AUTOSAR XML (schema 4-0-3)
standard types defined: Boolean, UInt16
package /AUTOSAR_Platform/DataConstrs
  range DC_Boolean: raw 0..1
  range DC_UInt16: raw 0..65535
package /PATAC/MSM/ComponentTypes
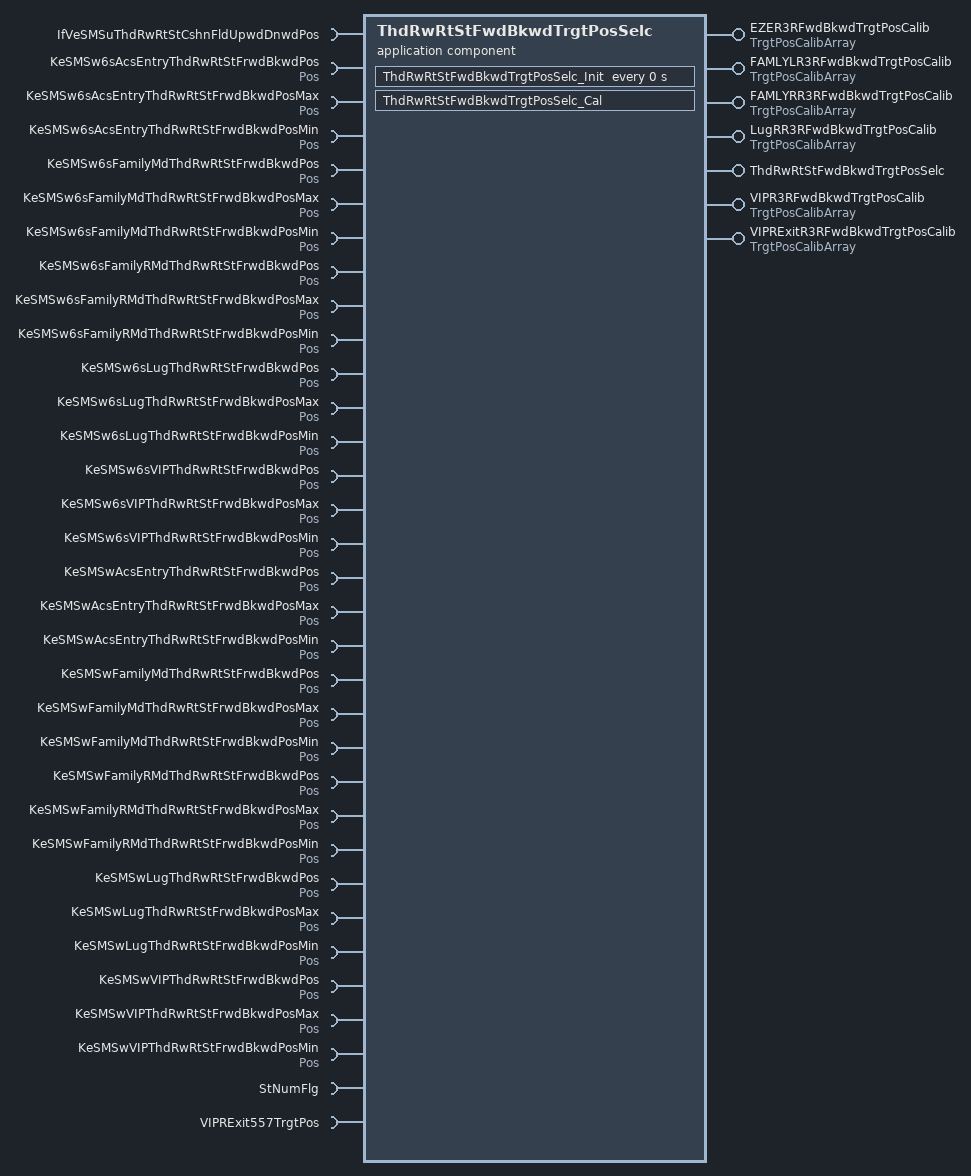
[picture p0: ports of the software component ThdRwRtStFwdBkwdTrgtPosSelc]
  application sw component type ThdRwRtStFwdBkwdTrgtPosSelc
    7 x provide port:
      EZER3RFwdBkwdTrgtPosCalib: nonqueued-sender-com-spec{data-element=TrgtPosArray, init-value=[4095, 4095, 4095]}, provided-interface=TrgtPosCalibArray
      FAMLYLR3RFwdBkwdTrgtPosCalib: nonqueued-sender-com-spec{data-element=TrgtPosArray, init-value=[4095, 4095, 4095]}, provided-interface=TrgtPosCalibArray
      FAMLYRR3RFwdBkwdTrgtPosCalib: nonqueued-sender-com-spec{data-element=TrgtPosArray, init-value=[4095, 4095, 4095]}, provided-interface=TrgtPosCalibArray
      LugRR3RFwdBkwdTrgtPosCalib: nonqueued-sender-com-spec{data-element=TrgtPosArray, init-value=[4095, 4095, 4095]}, provided-interface=TrgtPosCalibArray
      ThdRwRtStFwdBkwdTrgtPosSelc: server-com-spec{operation=Cal, queue-length=1}, provided-interface=ThdRwRtStFwdBkwdTrgtPosSelc
      VIPR3RFwdBkwdTrgtPosCalib: nonqueued-sender-com-spec{data-element=TrgtPosArray, init-value=[4095, 4095, 4095]}, provided-interface=TrgtPosCalibArray
      VIPRExitR3RFwdBkwdTrgtPosCalib: nonqueued-sender-com-spec{data-element=TrgtPosArray, init-value=[4095, 4095, 4095]}, provided-interface=TrgtPosCalibArray
    33 x require port:
      IfVeSMSuThdRwRtStCshnFldUpwdDnwdPos: nonqueued-receiver-com-spec{data-element=Val, filter=data-filter-type=ALWAYS, init-value=0}, required-interface=IfVeSMSuThdRwRtStCshnFldUpwdDnwdPos
      KeSMSw6sAcsEntryThdRwRtStFrwdBkwdPos: parameter-require-com-spec{init-value=2760, parameter=Val}, required-interface=Pos
      KeSMSw6sAcsEntryThdRwRtStFrwdBkwdPosMax: parameter-require-com-spec{init-value=4000, parameter=Val}, required-interface=Pos
      KeSMSw6sAcsEntryThdRwRtStFrwdBkwdPosMin: parameter-require-com-spec{init-value=2760, parameter=Val}, required-interface=Pos
      KeSMSw6sFamilyMdThdRwRtStFrwdBkwdPos: parameter-require-com-spec{init-value=0, parameter=Val}, required-interface=Pos
      KeSMSw6sFamilyMdThdRwRtStFrwdBkwdPosMax: parameter-require-com-spec{init-value=0, parameter=Val}, required-interface=Pos
      KeSMSw6sFamilyMdThdRwRtStFrwdBkwdPosMin: parameter-require-com-spec{init-value=0, parameter=Val}, required-interface=Pos
      KeSMSw6sFamilyRMdThdRwRtStFrwdBkwdPos: parameter-require-com-spec{init-value=0, parameter=Val}, required-interface=Pos
      KeSMSw6sFamilyRMdThdRwRtStFrwdBkwdPosMax: parameter-require-com-spec{init-value=0, parameter=Val}, required-interface=Pos
      KeSMSw6sFamilyRMdThdRwRtStFrwdBkwdPosMin: parameter-require-com-spec{init-value=0, parameter=Val}, required-interface=Pos
      KeSMSw6sLugThdRwRtStFrwdBkwdPos: parameter-require-com-spec{init-value=0, parameter=Val}, required-interface=Pos
      KeSMSw6sLugThdRwRtStFrwdBkwdPosMax: parameter-require-com-spec{init-value=0, parameter=Val}, required-interface=Pos
      KeSMSw6sLugThdRwRtStFrwdBkwdPosMin: parameter-require-com-spec{init-value=0, parameter=Val}, required-interface=Pos
      KeSMSw6sVIPThdRwRtStFrwdBkwdPos: parameter-require-com-spec{init-value=4000, parameter=Val}, required-interface=Pos
      KeSMSw6sVIPThdRwRtStFrwdBkwdPosMax: parameter-require-com-spec{init-value=4000, parameter=Val}, required-interface=Pos
      KeSMSw6sVIPThdRwRtStFrwdBkwdPosMin: parameter-require-com-spec{init-value=4000, parameter=Val}, required-interface=Pos
      KeSMSwAcsEntryThdRwRtStFrwdBkwdPos: parameter-require-com-spec{init-value=2760, parameter=Val}, required-interface=Pos
      KeSMSwAcsEntryThdRwRtStFrwdBkwdPosMax: parameter-require-com-spec{init-value=4000, parameter=Val}, required-interface=Pos
      KeSMSwAcsEntryThdRwRtStFrwdBkwdPosMin: parameter-require-com-spec{init-value=2760, parameter=Val}, required-interface=Pos
      KeSMSwFamilyMdThdRwRtStFrwdBkwdPos: parameter-require-com-spec{init-value=0, parameter=Val}, required-interface=Pos
      KeSMSwFamilyMdThdRwRtStFrwdBkwdPosMax: parameter-require-com-spec{init-value=0, parameter=Val}, required-interface=Pos
      KeSMSwFamilyMdThdRwRtStFrwdBkwdPosMin: parameter-require-com-spec{init-value=0, parameter=Val}, required-interface=Pos
      KeSMSwFamilyRMdThdRwRtStFrwdBkwdPos: parameter-require-com-spec{init-value=0, parameter=Val}, required-interface=Pos
      KeSMSwFamilyRMdThdRwRtStFrwdBkwdPosMax: parameter-require-com-spec{init-value=0, parameter=Val}, required-interface=Pos
      KeSMSwFamilyRMdThdRwRtStFrwdBkwdPosMin: parameter-require-com-spec{init-value=0, parameter=Val}, required-interface=Pos
      KeSMSwLugThdRwRtStFrwdBkwdPos: parameter-require-com-spec{init-value=0, parameter=Val}, required-interface=Pos
      KeSMSwLugThdRwRtStFrwdBkwdPosMax: parameter-require-com-spec{init-value=0, parameter=Val}, required-interface=Pos
      KeSMSwLugThdRwRtStFrwdBkwdPosMin: parameter-require-com-spec{init-value=0, parameter=Val}, required-interface=Pos
      KeSMSwVIPThdRwRtStFrwdBkwdPos: parameter-require-com-spec{init-value=4000, parameter=Val}, required-interface=Pos
      KeSMSwVIPThdRwRtStFrwdBkwdPosMax: parameter-require-com-spec{init-value=4000, parameter=Val}, required-interface=Pos
      KeSMSwVIPThdRwRtStFrwdBkwdPosMin: parameter-require-com-spec{init-value=4000, parameter=Val}, required-interface=Pos
      StNumFlg: required-interface=StNumFlg
        required-com-specs:
          data-element=Is4s, filter=data-filter-type=ALWAYS, init-value=0
          data-element=Is6s, filter=data-filter-type=ALWAYS, init-value=0
          data-element=Is6s7s, filter=data-filter-type=ALWAYS, init-value=0
          data-element=Is7s, filter=data-filter-type=ALWAYS, init-value=0
      VIPRExit557TrgtPos: required-com-specs=[Get, Set], required-interface=VIPRExit557TrgtPos
    behavior ThdRwRtStFwdBkwdTrgtPosSelc_InternalBehavior
      operation invoked event OIT_ThdRwRtStFwdBkwdTrgtPosSelc_Cal_ThdRwRtStFwdBkwdTrgtPosSelc_Cal: start-on-event=ThdRwRtStFwdBkwdTrgtPosSelc_Cal, operation=ThdRwRtStFwdBkwdTrgtPosSelc.Cal
      timing event ThdRwRtStFwdBkwdTrgtPosSelc_InitEvent: start-on-event=ThdRwRtStFwdBkwdTrgtPosSelc_Init, period=0
      runnable ThdRwRtStFwdBkwdTrgtPosSelc_Cal
        data-receive-point-by-arguments:
          5 x access:
            REC_IfVeSMSuThdRwRtStCshnFldUpwdDnwdPos_Val: accessed-variable=IfVeSMSuThdRwRtStCshnFldUpwdDnwdPos.Val
            REC_StNumFlg_Is4s: accessed-variable=StNumFlg.Is4s
            REC_StNumFlg_Is6s: accessed-variable=StNumFlg.Is6s
            REC_StNumFlg_Is6s7s: accessed-variable=StNumFlg.Is6s7s
            REC_StNumFlg_Is7s: accessed-variable=StNumFlg.Is7s
        data-send-points:
          6 x access:
            SEND_EZER3RFwdBkwdTrgtPosCalib_TrgtPosArray: accessed-variable=EZER3RFwdBkwdTrgtPosCalib.TrgtPosArray
            SEND_FAMLYLR3RFwdBkwdTrgtPosCalib_TrgtPosArray: accessed-variable=FAMLYLR3RFwdBkwdTrgtPosCalib.TrgtPosArray
            SEND_FAMLYRR3RFwdBkwdTrgtPosCalib_TrgtPosArray: accessed-variable=FAMLYRR3RFwdBkwdTrgtPosCalib.TrgtPosArray
            SEND_LugRR3RFwdBkwdTrgtPosCalib_TrgtPosArray: accessed-variable=LugRR3RFwdBkwdTrgtPosCalib.TrgtPosArray
            SEND_VIPR3RFwdBkwdTrgtPosCalib_TrgtPosArray: accessed-variable=VIPR3RFwdBkwdTrgtPosCalib.TrgtPosArray
            SEND_VIPRExitR3RFwdBkwdTrgtPosCalib_TrgtPosArray: accessed-variable=VIPRExitR3RFwdBkwdTrgtPosCalib.TrgtPosArray
        30 x parameter access:
          PA_KeSMSw6sAcsEntryThdRwRtStFrwdBkwdPos_Val: accessed-parameter=KeSMSw6sAcsEntryThdRwRtStFrwdBkwdPos.Val
          PA_KeSMSw6sAcsEntryThdRwRtStFrwdBkwdPosMax_Val: accessed-parameter=KeSMSw6sAcsEntryThdRwRtStFrwdBkwdPosMax.Val
          PA_KeSMSw6sAcsEntryThdRwRtStFrwdBkwdPosMin_Val: accessed-parameter=KeSMSw6sAcsEntryThdRwRtStFrwdBkwdPosMin.Val
          PA_KeSMSw6sFamilyMdThdRwRtStFrwdBkwdPos_Val: accessed-parameter=KeSMSw6sFamilyMdThdRwRtStFrwdBkwdPos.Val
          PA_KeSMSw6sFamilyMdThdRwRtStFrwdBkwdPosMax_Val: accessed-parameter=KeSMSw6sFamilyMdThdRwRtStFrwdBkwdPosMax.Val
          PA_KeSMSw6sFamilyMdThdRwRtStFrwdBkwdPosMin_Val: accessed-parameter=KeSMSw6sFamilyMdThdRwRtStFrwdBkwdPosMin.Val
          PA_KeSMSw6sFamilyRMdThdRwRtStFrwdBkwdPos_Val: accessed-parameter=KeSMSw6sFamilyRMdThdRwRtStFrwdBkwdPos.Val
          PA_KeSMSw6sFamilyRMdThdRwRtStFrwdBkwdPosMax_Val: accessed-parameter=KeSMSw6sFamilyRMdThdRwRtStFrwdBkwdPosMax.Val
          PA_KeSMSw6sFamilyRMdThdRwRtStFrwdBkwdPosMin_Val: accessed-parameter=KeSMSw6sFamilyRMdThdRwRtStFrwdBkwdPosMin.Val
          PA_KeSMSw6sLugThdRwRtStFrwdBkwdPos_Val: accessed-parameter=KeSMSw6sLugThdRwRtStFrwdBkwdPos.Val
          PA_KeSMSw6sLugThdRwRtStFrwdBkwdPosMax_Val: accessed-parameter=KeSMSw6sLugThdRwRtStFrwdBkwdPosMax.Val
          PA_KeSMSw6sLugThdRwRtStFrwdBkwdPosMin_Val: accessed-parameter=KeSMSw6sLugThdRwRtStFrwdBkwdPosMin.Val
          PA_KeSMSw6sVIPThdRwRtStFrwdBkwdPos_Val: accessed-parameter=KeSMSw6sVIPThdRwRtStFrwdBkwdPos.Val
          PA_KeSMSw6sVIPThdRwRtStFrwdBkwdPosMax_Val: accessed-parameter=KeSMSw6sVIPThdRwRtStFrwdBkwdPosMax.Val
          PA_KeSMSw6sVIPThdRwRtStFrwdBkwdPosMin_Val: accessed-parameter=KeSMSw6sVIPThdRwRtStFrwdBkwdPosMin.Val
          PA_KeSMSwAcsEntryThdRwRtStFrwdBkwdPos_Val: accessed-parameter=KeSMSwAcsEntryThdRwRtStFrwdBkwdPos.Val
          PA_KeSMSwAcsEntryThdRwRtStFrwdBkwdPosMax_Val: accessed-parameter=KeSMSwAcsEntryThdRwRtStFrwdBkwdPosMax.Val
          PA_KeSMSwAcsEntryThdRwRtStFrwdBkwdPosMin_Val: accessed-parameter=KeSMSwAcsEntryThdRwRtStFrwdBkwdPosMin.Val
          PA_KeSMSwFamilyMdThdRwRtStFrwdBkwdPos_Val: accessed-parameter=KeSMSwFamilyMdThdRwRtStFrwdBkwdPos.Val
          PA_KeSMSwFamilyMdThdRwRtStFrwdBkwdPosMax_Val: accessed-parameter=KeSMSwFamilyMdThdRwRtStFrwdBkwdPosMax.Val
          PA_KeSMSwFamilyMdThdRwRtStFrwdBkwdPosMin_Val: accessed-parameter=KeSMSwFamilyMdThdRwRtStFrwdBkwdPosMin.Val
          PA_KeSMSwFamilyRMdThdRwRtStFrwdBkwdPos_Val: accessed-parameter=KeSMSwFamilyRMdThdRwRtStFrwdBkwdPos.Val
          PA_KeSMSwFamilyRMdThdRwRtStFrwdBkwdPosMax_Val: accessed-parameter=KeSMSwFamilyRMdThdRwRtStFrwdBkwdPosMax.Val
          PA_KeSMSwFamilyRMdThdRwRtStFrwdBkwdPosMin_Val: accessed-parameter=KeSMSwFamilyRMdThdRwRtStFrwdBkwdPosMin.Val
          PA_KeSMSwLugThdRwRtStFrwdBkwdPos_Val: accessed-parameter=KeSMSwLugThdRwRtStFrwdBkwdPos.Val
          PA_KeSMSwLugThdRwRtStFrwdBkwdPosMax_Val: accessed-parameter=KeSMSwLugThdRwRtStFrwdBkwdPosMax.Val
          PA_KeSMSwLugThdRwRtStFrwdBkwdPosMin_Val: accessed-parameter=KeSMSwLugThdRwRtStFrwdBkwdPosMin.Val
          PA_KeSMSwVIPThdRwRtStFrwdBkwdPos_Val: accessed-parameter=KeSMSwVIPThdRwRtStFrwdBkwdPos.Val
          PA_KeSMSwVIPThdRwRtStFrwdBkwdPosMax_Val: accessed-parameter=KeSMSwVIPThdRwRtStFrwdBkwdPosMax.Val
          PA_KeSMSwVIPThdRwRtStFrwdBkwdPosMin_Val: accessed-parameter=KeSMSwVIPThdRwRtStFrwdBkwdPosMin.Val
        sync call SC_VIPRExit557TrgtPos_Get: operation=VIPRExit557TrgtPos.Get, timeout=0
      runnable ThdRwRtStFwdBkwdTrgtPosSelc_Init
        30 x parameter access:
          PA_KeSMSw6sAcsEntryThdRwRtStFrwdBkwdPos_Val: accessed-parameter=KeSMSw6sAcsEntryThdRwRtStFrwdBkwdPos.Val
          PA_KeSMSw6sAcsEntryThdRwRtStFrwdBkwdPosMax_Val: accessed-parameter=KeSMSw6sAcsEntryThdRwRtStFrwdBkwdPosMax.Val
          PA_KeSMSw6sAcsEntryThdRwRtStFrwdBkwdPosMin_Val: accessed-parameter=KeSMSw6sAcsEntryThdRwRtStFrwdBkwdPosMin.Val
          PA_KeSMSw6sFamilyMdThdRwRtStFrwdBkwdPos_Val: accessed-parameter=KeSMSw6sFamilyMdThdRwRtStFrwdBkwdPos.Val
          PA_KeSMSw6sFamilyMdThdRwRtStFrwdBkwdPosMax_Val: accessed-parameter=KeSMSw6sFamilyMdThdRwRtStFrwdBkwdPosMax.Val
          PA_KeSMSw6sFamilyMdThdRwRtStFrwdBkwdPosMin_Val: accessed-parameter=KeSMSw6sFamilyMdThdRwRtStFrwdBkwdPosMin.Val
          PA_KeSMSw6sFamilyRMdThdRwRtStFrwdBkwdPos_Val: accessed-parameter=KeSMSw6sFamilyRMdThdRwRtStFrwdBkwdPos.Val
          PA_KeSMSw6sFamilyRMdThdRwRtStFrwdBkwdPosMax_Val: accessed-parameter=KeSMSw6sFamilyRMdThdRwRtStFrwdBkwdPosMax.Val
          PA_KeSMSw6sFamilyRMdThdRwRtStFrwdBkwdPosMin_Val: accessed-parameter=KeSMSw6sFamilyRMdThdRwRtStFrwdBkwdPosMin.Val
          PA_KeSMSw6sLugThdRwRtStFrwdBkwdPos_Val: accessed-parameter=KeSMSw6sLugThdRwRtStFrwdBkwdPos.Val
          PA_KeSMSw6sLugThdRwRtStFrwdBkwdPosMax_Val: accessed-parameter=KeSMSw6sLugThdRwRtStFrwdBkwdPosMax.Val
          PA_KeSMSw6sLugThdRwRtStFrwdBkwdPosMin_Val: accessed-parameter=KeSMSw6sLugThdRwRtStFrwdBkwdPosMin.Val
          PA_KeSMSw6sVIPThdRwRtStFrwdBkwdPos_Val: accessed-parameter=KeSMSw6sVIPThdRwRtStFrwdBkwdPos.Val
          PA_KeSMSw6sVIPThdRwRtStFrwdBkwdPosMax_Val: accessed-parameter=KeSMSw6sVIPThdRwRtStFrwdBkwdPosMax.Val
          PA_KeSMSw6sVIPThdRwRtStFrwdBkwdPosMin_Val: accessed-parameter=KeSMSw6sVIPThdRwRtStFrwdBkwdPosMin.Val
          PA_KeSMSwAcsEntryThdRwRtStFrwdBkwdPos_Val: accessed-parameter=KeSMSwAcsEntryThdRwRtStFrwdBkwdPos.Val
          PA_KeSMSwAcsEntryThdRwRtStFrwdBkwdPosMax_Val: accessed-parameter=KeSMSwAcsEntryThdRwRtStFrwdBkwdPosMax.Val
          PA_KeSMSwAcsEntryThdRwRtStFrwdBkwdPosMin_Val: accessed-parameter=KeSMSwAcsEntryThdRwRtStFrwdBkwdPosMin.Val
          PA_KeSMSwFamilyMdThdRwRtStFrwdBkwdPos_Val: accessed-parameter=KeSMSwFamilyMdThdRwRtStFrwdBkwdPos.Val
          PA_KeSMSwFamilyMdThdRwRtStFrwdBkwdPosMax_Val: accessed-parameter=KeSMSwFamilyMdThdRwRtStFrwdBkwdPosMax.Val
          PA_KeSMSwFamilyMdThdRwRtStFrwdBkwdPosMin_Val: accessed-parameter=KeSMSwFamilyMdThdRwRtStFrwdBkwdPosMin.Val
          PA_KeSMSwFamilyRMdThdRwRtStFrwdBkwdPos_Val: accessed-parameter=KeSMSwFamilyRMdThdRwRtStFrwdBkwdPos.Val
          PA_KeSMSwFamilyRMdThdRwRtStFrwdBkwdPosMax_Val: accessed-parameter=KeSMSwFamilyRMdThdRwRtStFrwdBkwdPosMax.Val
          PA_KeSMSwFamilyRMdThdRwRtStFrwdBkwdPosMin_Val: accessed-parameter=KeSMSwFamilyRMdThdRwRtStFrwdBkwdPosMin.Val
          PA_KeSMSwLugThdRwRtStFrwdBkwdPos_Val: accessed-parameter=KeSMSwLugThdRwRtStFrwdBkwdPos.Val
          PA_KeSMSwLugThdRwRtStFrwdBkwdPosMax_Val: accessed-parameter=KeSMSwLugThdRwRtStFrwdBkwdPosMax.Val
          PA_KeSMSwLugThdRwRtStFrwdBkwdPosMin_Val: accessed-parameter=KeSMSwLugThdRwRtStFrwdBkwdPosMin.Val
          PA_KeSMSwVIPThdRwRtStFrwdBkwdPos_Val: accessed-parameter=KeSMSwVIPThdRwRtStFrwdBkwdPos.Val
          PA_KeSMSwVIPThdRwRtStFrwdBkwdPosMax_Val: accessed-parameter=KeSMSwVIPThdRwRtStFrwdBkwdPosMax.Val
          PA_KeSMSwVIPThdRwRtStFrwdBkwdPosMin_Val: accessed-parameter=KeSMSwVIPThdRwRtStFrwdBkwdPosMin.Val
  swc implementation ThdRwRtStFwdBkwdTrgtPosSelc_Implementation: behavior=ThdRwRtStFwdBkwdTrgtPosSelc_InternalBehavior
    code-descriptors:
      code Default: artifact-descriptors=autosar-engineering-object={short-label=Default, category=SWSRC}
package /PATAC/MSM/ModeAdjust/CalPortInterface
  parameter interface Pos
    parameter data prototype Val: sw-calibration-access=READ-WRITE, type=UInt16
package /PATAC/MSM/ModeAdjust/DataType
  impl type TrgtPosCalibArray: category=ARRAY, sw-calibration-access=READ-ONLY, type-emitter=RTE  # 0:pos 1:max 2:min
    element Element: array-size=3, array-size-semantics=FIXED-SIZE, implementation-data-type=UInt16, invalid-value=0
package /PATAC/MSM/ModeAdjust/Interfaces
  sender receiver interface IfVeSMSuThdRwRtStCshnFldUpwdDnwdPos: invalidation-policy{data-element=Val, handle-invalid=DONT-INVALIDATE}
    data Val: type=UInt16
package /PATAC/MSM/ModeAdjust/PortInterface
  client server interface ThdRwRtStFwdBkwdTrgtPosSelc
    operation Cal
  client server interface VIPRExit557TrgtPos
    operation Get
      11 x arg, all with type=UInt16, direction=OUT, server-argument-impl-policy=USE-ARGUMENT-TYPE:
        SecRwRtStBkReclnTrgtPos
        SecRwRtStZeroTrgtPos
        SecRwRtStLgrstUpwdDnwdTrgtPos
        SecRwRtStLgrstInwdOtwdTrgtPos
        ThdRwLtStBkReclnTrgtPos
        ThdRwLtStFwdBkwdTrgtPos
        ThdRwRtStBkReclnTrgtPos
        ThdRwRtStFwdBkwdTrgtPos
        PassStBkReclnTrgtPos
        PassStFwdBkwdTrgtPos
        SecRwRtStFwdBkwdTrgtPos
    operation Set
  sender receiver interface StNumFlg
    4 x data, all with type=Boolean:
      Is4s
      Is6s
      Is6s7s
      Is7s
    invalidation-policys:
      data-element=Is4s, handle-invalid=DONT-INVALIDATE
      data-element=Is6s, handle-invalid=DONT-INVALIDATE
      data-element=Is6s7s, handle-invalid=DONT-INVALIDATE
      data-element=Is7s, handle-invalid=DONT-INVALIDATE
  sender receiver interface TrgtPosCalibArray: invalidation-policy{data-element=TrgtPosArray, handle-invalid=DONT-INVALIDATE}
    data TrgtPosArray: type=TrgtPosCalibArray  # 0:Pos 1:Max 2:Min
